AUTOSAR XML (schema 00048)
package /AUTOLIV/SoftwareComponents/ERH
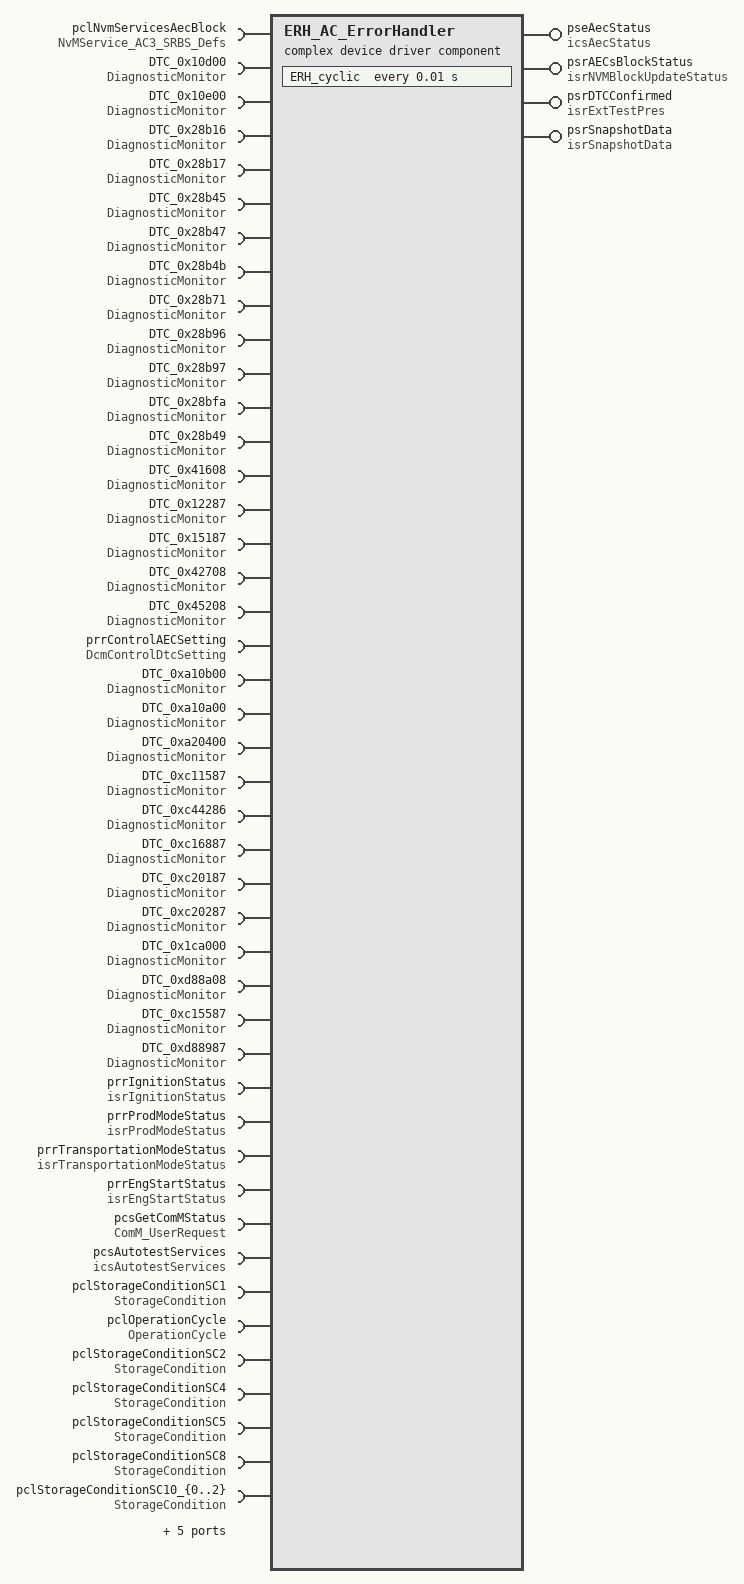
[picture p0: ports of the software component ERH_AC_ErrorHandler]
  complex device driver sw component type ERH_AC_ErrorHandler
    provide port pseAecStatus: provided-interface=icsAecStatus
      provided-com-specs:
        operation=GetAecDeskillThrs, queue-length=1
        operation=GetAecGroupsStatus, queue-length=1
        operation=GetAecNvpBlockRecordingStatus, queue-length=1
        operation=GetAecQualificationCount, queue-length=1
        operation=GetAecStatus, queue-length=1
        operation=GetNumberOfImplementedAec, queue-length=1
        operation=SetAecEvent, queue-length=1
    31 x require port:
      pclNvmServicesAecBlock: required-com-specs=[EraseBlock, InvalidateNvBlock, RestoreBlockDefaults, WriteBlock, ReadBlock, SetRamBlockStatus, GetErrorStatus], required-interface=NvMService_AC3_SRBS_Defs
      DTC_0x10d00: required-interface=DiagnosticMonitor
        required-com-specs:
          GetEventExtendedDataRecordEx
          GetEventFreezeFrameDataEx
          GetFaultDetectionCounter
          GetDTCOfEvent
          GetEventTested
          GetEventFailed
          GetEventStatus
          GetEventUdsStatus
          ResetEventDebounceStatus
          ResetEventStatus
          SetEventStatus
      DTC_0x10e00: required-interface=DiagnosticMonitor
        required-com-specs:
          GetEventExtendedDataRecordEx
          GetEventFreezeFrameDataEx
          GetFaultDetectionCounter
          GetDTCOfEvent
          GetEventTested
          GetEventFailed
          GetEventStatus
          GetEventUdsStatus
          ResetEventDebounceStatus
          ResetEventStatus
          SetEventStatus
      DTC_0x28b16: required-interface=DiagnosticMonitor
        required-com-specs:
          GetEventExtendedDataRecordEx
          GetEventFreezeFrameDataEx
          GetFaultDetectionCounter
          GetDTCOfEvent
          GetEventTested
          GetEventFailed
          GetEventStatus
          GetEventUdsStatus
          ResetEventDebounceStatus
          ResetEventStatus
          SetEventStatus
      DTC_0x28b17: required-interface=DiagnosticMonitor
        required-com-specs:
          GetEventExtendedDataRecordEx
          GetEventFreezeFrameDataEx
          GetFaultDetectionCounter
          GetDTCOfEvent
          GetEventTested
          GetEventFailed
          GetEventStatus
          GetEventUdsStatus
          ResetEventDebounceStatus
          ResetEventStatus
          SetEventStatus
      DTC_0x28b45: required-interface=DiagnosticMonitor
        required-com-specs:
          GetEventExtendedDataRecordEx
          GetEventFreezeFrameDataEx
          GetFaultDetectionCounter
          GetDTCOfEvent
          GetEventTested
          GetEventFailed
          GetEventStatus
          GetEventUdsStatus
          ResetEventDebounceStatus
          ResetEventStatus
          SetEventStatus
      DTC_0x28b47: required-interface=DiagnosticMonitor
        required-com-specs:
          GetEventExtendedDataRecordEx
          GetEventFreezeFrameDataEx
          GetFaultDetectionCounter
          GetDTCOfEvent
          GetEventTested
          GetEventFailed
          GetEventStatus
          GetEventUdsStatus
          ResetEventDebounceStatus
          ResetEventStatus
          SetEventStatus
      DTC_0x28b4b: required-interface=DiagnosticMonitor
        required-com-specs:
          GetEventExtendedDataRecordEx
          GetEventFreezeFrameDataEx
          GetFaultDetectionCounter
          GetDTCOfEvent
          GetEventTested
          GetEventFailed
          GetEventStatus
          GetEventUdsStatus
          ResetEventDebounceStatus
          ResetEventStatus
          SetEventStatus
      DTC_0x28b71: required-interface=DiagnosticMonitor
        required-com-specs:
          GetEventExtendedDataRecordEx
          GetEventFreezeFrameDataEx
          GetFaultDetectionCounter
          GetDTCOfEvent
          GetEventTested
          GetEventFailed
          GetEventStatus
          GetEventUdsStatus
          ResetEventDebounceStatus
          ResetEventStatus
          SetEventStatus
      DTC_0x28b96: required-interface=DiagnosticMonitor
        required-com-specs:
          GetEventExtendedDataRecordEx
          GetEventFreezeFrameDataEx
          GetFaultDetectionCounter
          GetDTCOfEvent
          GetEventTested
          GetEventFailed
          GetEventStatus
          GetEventUdsStatus
          ResetEventDebounceStatus
          ResetEventStatus
          SetEventStatus
      DTC_0x28b97: required-interface=DiagnosticMonitor
        required-com-specs:
          GetEventExtendedDataRecordEx
          GetEventFreezeFrameDataEx
          GetFaultDetectionCounter
          GetDTCOfEvent
          GetEventTested
          GetEventFailed
          GetEventStatus
          GetEventUdsStatus
          ResetEventDebounceStatus
          ResetEventStatus
          SetEventStatus
      DTC_0x28bfa: required-interface=DiagnosticMonitor
        required-com-specs:
          GetEventExtendedDataRecordEx
          GetEventFreezeFrameDataEx
          GetFaultDetectionCounter
          GetDTCOfEvent
          GetEventTested
          GetEventFailed
          GetEventStatus
          GetEventUdsStatus
          ResetEventDebounceStatus
          ResetEventStatus
          SetEventStatus
      DTC_0x28b49: required-interface=DiagnosticMonitor
        required-com-specs:
          GetEventExtendedDataRecordEx
          GetEventFreezeFrameDataEx
          GetFaultDetectionCounter
          GetDTCOfEvent
          GetEventTested
          GetEventFailed
          GetEventStatus
          GetEventUdsStatus
          ResetEventDebounceStatus
          ResetEventStatus
          SetEventStatus
      DTC_0x41608: required-interface=DiagnosticMonitor
        required-com-specs:
          GetEventExtendedDataRecordEx
          GetEventFreezeFrameDataEx
          GetFaultDetectionCounter
          GetDTCOfEvent
          GetEventTested
          GetEventFailed
          GetEventStatus
          GetEventUdsStatus
          ResetEventDebounceStatus
          ResetEventStatus
          SetEventStatus
      DTC_0x12287: required-interface=DiagnosticMonitor
        required-com-specs:
          GetEventExtendedDataRecordEx
          GetEventFreezeFrameDataEx
          GetFaultDetectionCounter
          GetDTCOfEvent
          GetEventTested
          GetEventFailed
          GetEventStatus
          GetEventUdsStatus
          ResetEventDebounceStatus
          ResetEventStatus
          SetEventStatus
      DTC_0x15187: required-interface=DiagnosticMonitor
        required-com-specs:
          GetEventExtendedDataRecordEx
          GetEventFreezeFrameDataEx
          GetFaultDetectionCounter
          GetDTCOfEvent
          GetEventTested
          GetEventFailed
          GetEventStatus
          GetEventUdsStatus
          ResetEventDebounceStatus
          ResetEventStatus
          SetEventStatus
      DTC_0x42708: required-interface=DiagnosticMonitor
        required-com-specs:
          GetEventExtendedDataRecordEx
          GetEventFreezeFrameDataEx
          GetFaultDetectionCounter
          GetDTCOfEvent
          GetEventTested
          GetEventFailed
          GetEventStatus
          GetEventUdsStatus
          ResetEventDebounceStatus
          ResetEventStatus
          SetEventStatus
      DTC_0x45208: required-interface=DiagnosticMonitor
        required-com-specs:
          GetEventExtendedDataRecordEx
          GetEventFreezeFrameDataEx
          GetFaultDetectionCounter
          GetDTCOfEvent
          GetEventTested
          GetEventFailed
          GetEventStatus
          GetEventUdsStatus
          ResetEventDebounceStatus
          ResetEventStatus
          SetEventStatus
      prrControlAECSetting: mode-switch-receiver-com-spec=DcmControlDtcSetting, required-interface=DcmControlDtcSetting
      DTC_0xa10b00: required-interface=DiagnosticMonitor
        required-com-specs:
          GetEventExtendedDataRecordEx
          GetEventFreezeFrameDataEx
          GetFaultDetectionCounter
          GetDTCOfEvent
          GetEventTested
          GetEventFailed
          GetEventStatus
          GetEventUdsStatus
          ResetEventDebounceStatus
          ResetEventStatus
          SetEventStatus
      DTC_0xa10a00: required-interface=DiagnosticMonitor
        required-com-specs:
          GetEventExtendedDataRecordEx
          GetEventFreezeFrameDataEx
          GetFaultDetectionCounter
          GetDTCOfEvent
          GetEventTested
          GetEventFailed
          GetEventStatus
          GetEventUdsStatus
          ResetEventDebounceStatus
          ResetEventStatus
          SetEventStatus
      DTC_0xa20400: required-interface=DiagnosticMonitor
        required-com-specs:
          GetEventExtendedDataRecordEx
          GetEventFreezeFrameDataEx
          GetFaultDetectionCounter
          GetDTCOfEvent
          GetEventTested
          GetEventFailed
          GetEventStatus
          GetEventUdsStatus
          ResetEventDebounceStatus
          ResetEventStatus
          SetEventStatus
      DTC_0xc11587: required-interface=DiagnosticMonitor
        required-com-specs:
          GetEventExtendedDataRecordEx
          GetEventFreezeFrameDataEx
          GetFaultDetectionCounter
          GetDTCOfEvent
          GetEventTested
          GetEventFailed
          GetEventStatus
          GetEventUdsStatus
          ResetEventDebounceStatus
          ResetEventStatus
          SetEventStatus
      DTC_0xc44286: required-interface=DiagnosticMonitor
        required-com-specs:
          GetEventExtendedDataRecordEx
          GetEventFreezeFrameDataEx
          GetFaultDetectionCounter
          GetDTCOfEvent
          GetEventTested
          GetEventFailed
          GetEventStatus
          GetEventUdsStatus
          ResetEventDebounceStatus
          ResetEventStatus
          SetEventStatus
      DTC_0xc16887: required-interface=DiagnosticMonitor
        required-com-specs:
          GetEventExtendedDataRecordEx
          GetEventFreezeFrameDataEx
          GetFaultDetectionCounter
          GetDTCOfEvent
          GetEventTested
          GetEventFailed
          GetEventStatus
          GetEventUdsStatus
          ResetEventDebounceStatus
          ResetEventStatus
          SetEventStatus
      DTC_0xc20187: required-interface=DiagnosticMonitor
        required-com-specs:
          GetEventExtendedDataRecordEx
          GetEventFreezeFrameDataEx
          GetFaultDetectionCounter
          GetDTCOfEvent
          GetEventTested
          GetEventFailed
          GetEventStatus
          GetEventUdsStatus
          ResetEventDebounceStatus
          ResetEventStatus
          SetEventStatus
      DTC_0xc20287: required-interface=DiagnosticMonitor
        required-com-specs:
          GetEventExtendedDataRecordEx
          GetEventFreezeFrameDataEx
          GetFaultDetectionCounter
          GetDTCOfEvent
          GetEventTested
          GetEventFailed
          GetEventStatus
          GetEventUdsStatus
          ResetEventDebounceStatus
          ResetEventStatus
          SetEventStatus
      DTC_0x1ca000: required-interface=DiagnosticMonitor
        required-com-specs:
          GetEventExtendedDataRecordEx
          GetEventFreezeFrameDataEx
          GetFaultDetectionCounter
          GetDTCOfEvent
          GetEventTested
          GetEventFailed
          GetEventStatus
          GetEventUdsStatus
          ResetEventDebounceStatus
          ResetEventStatus
          SetEventStatus
      DTC_0xd88a08: required-interface=DiagnosticMonitor
        required-com-specs:
          GetEventExtendedDataRecordEx
          GetEventFreezeFrameDataEx
          GetFaultDetectionCounter
          GetDTCOfEvent
          GetEventTested
          GetEventFailed
          GetEventStatus
          GetEventUdsStatus
          ResetEventDebounceStatus
          ResetEventStatus
          SetEventStatus
      DTC_0xc15587: required-interface=DiagnosticMonitor
        required-com-specs:
          GetEventExtendedDataRecordEx
          GetEventFreezeFrameDataEx
          GetFaultDetectionCounter
          GetDTCOfEvent
          GetEventTested
          GetEventFailed
          GetEventStatus
          GetEventUdsStatus
          ResetEventDebounceStatus
          ResetEventStatus
          SetEventStatus
      DTC_0xd88987: required-interface=DiagnosticMonitor
        required-com-specs:
          GetEventExtendedDataRecordEx
          GetEventFreezeFrameDataEx
          GetFaultDetectionCounter
          GetDTCOfEvent
          GetEventTested
          GetEventFailed
          GetEventStatus
          GetEventUdsStatus
          ResetEventDebounceStatus
          ResetEventStatus
          SetEventStatus
    provide port psrAECsBlockStatus: nonqueued-sender-com-spec=b8NVMBlockStatus, provided-interface=isrNVMBlockUpdateStatus
    19 x require port:
      prrIgnitionStatus: required-interface=isrIgnitionStatus
        required-com-specs:
          data-element=b8TriggerIgnitionStatus, filter=data-filter-type=ALWAYS, init-value=constant-reference=APPLINIT_KB8_BOOLEAN_FALSE
          data-element=b8TriggerIgnitionStatusEnableStorageCondition, filter=data-filter-type=ALWAYS, init-value=constant-reference=APPLINIT_KB8_BOOLEAN_FALSE
      prrProdModeStatus: nonqueued-receiver-com-spec{data-element=b8TriggerProdModeStatus, filter=data-filter-type=ALWAYS, init-value=constant-reference=APPLINIT_KB8_BOOLEAN_TRUE}, required-interface=isrProdModeStatus
      prrTransportationModeStatus: nonqueued-receiver-com-spec{data-element=b8TransportationModeStatus, filter=data-filter-type=ALWAYS, init-value=constant-reference=APPLINIT_KB8_BOOLEAN_TRUE}, required-interface=isrTransportationModeStatus
      prrEngStartStatus: nonqueued-receiver-com-spec{data-element=b8EngStartStatus, filter=data-filter-type=ALWAYS, init-value=constant-reference=APPLINIT_KB8_BOOLEAN_FALSE}, required-interface=isrEngStartStatus
      pcsGetComMStatus: required-com-specs=[GetCurrentPNCComMode, GetRequestedComMode, GetMaxComMode, GetCurrentComMode, RequestComMode], required-interface=ComM_UserRequest
      pcsAutotestServices: required-com-specs=[GetTestResult, GetLastCriticalAutotestID], required-interface=icsAutotestServices
      pclStorageConditionSC1: client-com-spec=SetStorageCondition, required-interface=StorageCondition
      pclOperationCycle: client-com-spec=SetOperationCycleState, required-interface=OperationCycle
      pclStorageConditionSC2: client-com-spec=SetStorageCondition, required-interface=StorageCondition
      pclStorageConditionSC4: client-com-spec=SetStorageCondition, required-interface=StorageCondition
      pclStorageConditionSC5: client-com-spec=SetStorageCondition, required-interface=StorageCondition
      pclStorageConditionSC8: client-com-spec=SetStorageCondition, required-interface=StorageCondition
      pclStorageConditionSC10_{0..2}: client-com-spec=SetStorageCondition, required-interface=StorageCondition
      pclStorageConditionSC11: client-com-spec=SetStorageCondition, required-interface=StorageCondition
      pclStorageConditionSC12: client-com-spec=SetStorageCondition, required-interface=StorageCondition
      pclStorageConditionSC3: client-com-spec=SetStorageCondition, required-interface=StorageCondition
      pcl_GetDTCStatus: required-interface=GeneralDiagnosticInfo
        required-com-specs:
          GetMonitorStatus
          GetDebouncingOfEvent
          GetEventEnableCondition
          GetEventExtendedDataRecordEx
          GetEventFreezeFrameDataEx
          GetFaultDetectionCounter
          GetDTCOfEvent
          GetEventTested
          GetEventFailed
          GetEventStatus
          GetEventUdsStatus
    provide port psrDTCConfirmed: provided-interface=isrExtTestPres
      provided-com-specs:
        data-element=b8DTCConfirmed, init-value=constant-reference=APPLINIT_KB8_BOOLEAN_FALSE
        data-element=b8ExtTesterPresent, init-value=constant-reference=APPLINIT_KB8_BOOLEAN_FALSE
    provide port psrSnapshotData: nonqueued-sender-com-spec{data-element=u8SnapshotAecId, init-value=255}, provided-interface=isrSnapshotData
    require port isrSupBatStatus: nonqueued-receiver-com-spec{data-element=b8SupBatStatus, filter=data-filter-type=ALWAYS, init-value=constant-reference=APPLINIT_KB8_BOOLEAN_FALSE}, required-interface=isrSupBatStatus
    behavior ERH_IB_ErrorHandler: data-type-mapping=DataTypeMappingSet_PP4G, port-api-option{enable-take-address=false, error-handling=NO-TRANSFORMER-ERROR-HANDLING, indirect-api=false, port=pclOperationCycle}
      7 x operation invoked event:
        oie_pseAecStatus_GetAecDeskillThrs: start-on-event=ERH_runGetAecDeskillThrs, operation=pseAecStatus.GetAecDeskillThrs
        oie_pseAecStatus_GetAecGroupsStatus: start-on-event=ERH_runGetAecGroupsStatus, operation=pseAecStatus.GetAecGroupsStatus
        oie_pseAecStatus_GetAecNvpBlockRecordingStatus: start-on-event=ERH_runGetAecNvpBlockRecordingStatus, operation=pseAecStatus.GetAecNvpBlockRecordingStatus
        oie_pseAecStatus_GetAecQualificationCount: start-on-event=ERH_runGetAecQualificationCount, operation=pseAecStatus.GetAecQualificationCount
        oie_pseAecStatus_GetAecStatus: start-on-event=ERH_runGetAecStatus, operation=pseAecStatus.GetAecStatus
        oie_pseAecStatus_GetNumberOfImplementedAec: start-on-event=ERH_runGetNumberOfImplementedAec, operation=pseAecStatus.GetNumberOfImplementedAec
        oie_pseAecStatus_SetAecEvent: start-on-event=ERH_runSetAecEvent, operation=pseAecStatus.SetAecEvent
      init event ERH_InitEvent: start-on-event=ERH_Init
      timing event TMT_ERH_cyclic: start-on-event=ERH_cyclic, period=0.01
      10 x runnable:
        ERH_Init
          data-receive-point-by-arguments:
            access REC_prrIgnitionStatus_b8TriggerIgnitionStatus: accessed-variable=prrIgnitionStatus.b8TriggerIgnitionStatus
            access REC_prrIgnitionStatus_b8TriggerIgnitionStatusEnableStorageCondition: accessed-variable=prrIgnitionStatus.b8TriggerIgnitionStatusEnableStorageCondition
          9 x sync call:
            SC_pclNvmServicesAecBlock_EraseBlock: operation=pclNvmServicesAecBlock.EraseBlock
            SC_pclNvmServicesAecBlock_GetErrorStatus: operation=pclNvmServicesAecBlock.GetErrorStatus
            SC_pclNvmServicesAecBlock_InvalidateNvBlock: operation=pclNvmServicesAecBlock.InvalidateNvBlock
            SC_pclNvmServicesAecBlock_ReadBlock: operation=pclNvmServicesAecBlock.ReadBlock
            SC_pclNvmServicesAecBlock_RestoreBlockDefaults: operation=pclNvmServicesAecBlock.RestoreBlockDefaults
            SC_pclNvmServicesAecBlock_SetRamBlockStatus: operation=pclNvmServicesAecBlock.SetRamBlockStatus
            SC_pclNvmServicesAecBlock_WriteBlock: operation=pclNvmServicesAecBlock.WriteBlock
            SC_DTC_0x28b4b_SetEventStatus: operation=DTC_0x28b4b.SetEventStatus
            SC_pclOperationCycle_SetOperationCycleState: operation=pclOperationCycle.SetOperationCycleState
        ERH_runGetAecDeskillThrs: can-be-invoked-concurrently=true
        ERH_runGetAecGroupsStatus: can-be-invoked-concurrently=true
        ERH_runGetAecNvpBlockRecordingStatus: can-be-invoked-concurrently=true
        ERH_runGetAecQualificationCount
        ERH_runGetAecStatus: can-be-invoked-concurrently=true
        ERH_runGetNumberOfImplementedAec: can-be-invoked-concurrently=true
        ERH_runSetAecEvent: can-be-invoked-concurrently=true, mode-access-point=prrControlAECSetting.DcmControlDtcSetting
          data-send-points:
            access SEND_psrAECsBlockStatus_b8NVMBlockStatus: accessed-variable=psrAECsBlockStatus.b8NVMBlockStatus
          29 x sync call:
            SC_DTC__SetEventStatus: operation=DTC_0x10d00.SetEventStatus
            SC_DTC_0x10e00_SetEventStatus: operation=DTC_0x10e00.SetEventStatus
            SC_DTC_0x28b16_SetEventStatus: operation=DTC_0x28b16.SetEventStatus
            SC_DTC_0x28b17_SetEventStatus: operation=DTC_0x28b17.SetEventStatus
            SC_DTC_0x28b45_SetEventStatus: operation=DTC_0x28b45.SetEventStatus
            SC_DTC_0x28b47_SetEventStatus: operation=DTC_0x28b47.SetEventStatus
            SC_DTC_0x28b71_SetEventStatus: operation=DTC_0x28b71.SetEventStatus
            SC_DTC_0x28b96_SetEventStatus: operation=DTC_0x28b96.SetEventStatus
            SC_DTC_0x28b97_SetEventStatus: operation=DTC_0x28b97.SetEventStatus
            SC_DTC_0x28bfa_SetEventStatus: operation=DTC_0x28bfa.SetEventStatus
            SC_DTC_0x28b49_SetEventStatus: operation=DTC_0x28b49.SetEventStatus
            SC_DTC_0x28b4b_SetEventStatus: operation=DTC_0x28b4b.SetEventStatus
            SC_DTC_0x41608_SetEventStatus: operation=DTC_0x41608.SetEventStatus
            SC_DTC_0x42708_SetEventStatus: operation=DTC_0x42708.SetEventStatus
            SC_DTC_0x45208_SetEventStatus: operation=DTC_0x45208.SetEventStatus
            SC_DTC_0x12287_SetEventStatus: operation=DTC_0x12287.SetEventStatus
            SC_DTC_0x15187_SetEventStatus: operation=DTC_0x15187.SetEventStatus
            SC_DTC_0xa10a00_SetEventStatus: operation=DTC_0xa10a00.SetEventStatus
            SC_DTC_0xa10b00_SetEventStatus: operation=DTC_0xa10b00.SetEventStatus
            SC_DTC_0xa20400_SetEventStatus: operation=DTC_0xa20400.SetEventStatus
            SC_DTC_0xc11587_SetEventStatus: operation=DTC_0xc11587.SetEventStatus
            SC_DTC_0xc16887_SetEventStatus: operation=DTC_0xc16887.SetEventStatus
            SC_DTC_0xc20187_SetEventStatus: operation=DTC_0xc20187.SetEventStatus
            SC_DTC_0xc20287_SetEventStatus: operation=DTC_0xc20287.SetEventStatus
            SC_DTC_0xc44286_SetEventStatus: operation=DTC_0xc44286.SetEventStatus
            SC_DTC_0xca000_SetEventStatus: operation=DTC_0x1ca000.SetEventStatus
            SC_DTC_0x15587_SetEventStatus: operation=DTC_0xc15587.SetEventStatus
            SC_DTC_0x88987_SetEventStatus: operation=DTC_0xd88987.SetEventStatus
            SC_DTC_0xd88a08_SetEventStatus: operation=DTC_0xd88a08.SetEventStatus
        ERH_runStoreEverQualifiedAECsToNVP
        ERH_cyclic
          data-receive-point-by-arguments:
            4 x access:
              REC_prrProdModeStatus_b8TriggerProdModeStatus: accessed-variable=prrProdModeStatus.b8TriggerProdModeStatus
              REC_prrTransportationModeStatus_b8TransportationModeStatus: accessed-variable=prrTransportationModeStatus.b8TransportationModeStatus
              REC_prrEngStartStatus_b8EngStartStatus: accessed-variable=prrEngStartStatus.b8EngStartStatus
              REC_isrSupBatStatus_b8EngStartStatus: accessed-variable=isrSupBatStatus.b8SupBatStatus
          data-send-points:
            access SEND_psrDTCConfirmed_b8DTCConfirmed: accessed-variable=psrDTCConfirmed.b8DTCConfirmed
            access SEND_psrSnapshotData_u8SnapshotAecId: accessed-variable=psrSnapshotData.u8SnapshotAecId
          14 x sync call:
            SC_pcsAutotestServices_GetTestResult: operation=pcsAutotestServices.GetTestResult
            SC_pcsGetComMStatus_GetCurrentComMode: operation=pcsGetComMStatus.GetCurrentComMode
            SC_pclStorageConditionSC10_2_SetStorageCondition: operation=pclStorageConditionSC10_2.SetStorageCondition
            SC_pclStorageConditionSC11_SetStorageCondition: operation=pclStorageConditionSC11.SetStorageCondition
            SC_pclStorageConditionSC12_SetStorageCondition: operation=pclStorageConditionSC12.SetStorageCondition
            SC_pclStorageConditionSC{2..5}_SetStorageCondition: operation=pclStorageConditionSC{2..5}.SetStorageCondition
            SC_pclStorageConditionSC8_SetStorageCondition: operation=pclStorageConditionSC8.SetStorageCondition
            SC_pclStorageConditionSC1_SetStorageCondition: operation=pclStorageConditionSC1.SetStorageCondition
            SC_pclStorageConditionSC10_0_SetStorageCondition: operation=pclStorageConditionSC10_0.SetStorageCondition
            SC_pclStorageConditionSC10_1_SetStorageCondition: operation=pclStorageConditionSC10_1.SetStorageCondition
            SC_pcl_GetDTCStatus_GetEventStatus: operation=pcl_GetDTCStatus.GetEventStatus
  swc implementation ERH_AC_ErrorHandler_Implementation: behavior=ERH_IB_ErrorHandler
